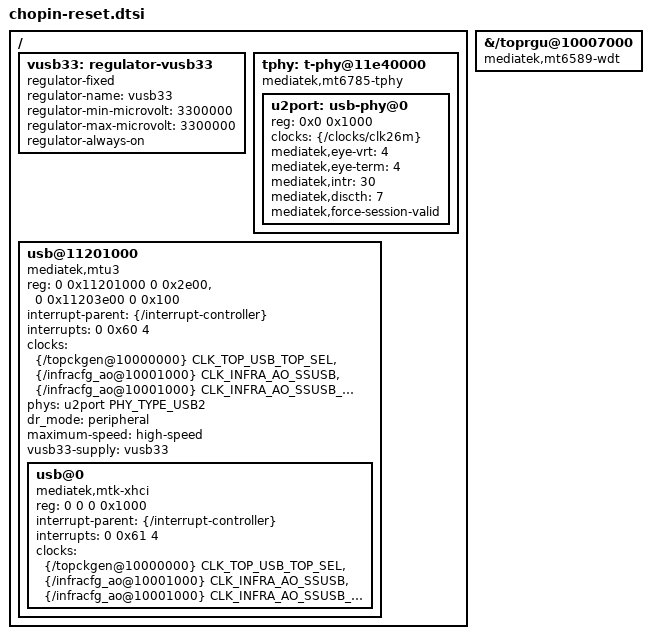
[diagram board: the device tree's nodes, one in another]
// SPDX-License-Identifier: GPL-2.0-only
/*
 * chopin: top reset controller.
 */

&{/toprgu@10007000} {
	compatible = "mediatek,mt6589-wdt", "mediatek,toprgu";
	status = "okay";
};

/ {
	/* mtu3 requires vusb33-supply; LK has already powered it */
	vusb33: regulator-vusb33 {
		compatible = "regulator-fixed";
		regulator-name = "vusb33";
		regulator-min-microvolt = <3300000>;
		regulator-max-microvolt = <3300000>;
		regulator-always-on;
	};

	tphy: t-phy@11e40000 {
		compatible = "mediatek,mt6785-tphy", "mediatek,generic-tphy-v2";
		#address-cells = <1>;
		#size-cells = <1>;
		/*
		 * 4 KiB, not the 0x400 the MT6895 port used: the vendor's
		 * analog rail register (USB30_PHYA_REG1) sits at +0xb04, well
		 * outside a 0x400 window, and the driver has to be able to
		 * reach it.  Everything mainline uses (misc 0x000, freq 0x100,
		 * com 0x300) is unaffected.
		 */
		ranges = <0 0 0x11e40000 0x1000>;
		status = "okay";

		u2port: usb-phy@0 {
			reg = <0x0 0x1000>;
			clocks = <&{/clocks/clk26m}>;
			clock-names = "ref";
			#phy-cells = <1>;

			mediatek,eye-vrt = <4>;
			mediatek,eye-term = <4>;
			mediatek,intr = <30>;
			mediatek,discth = <7>;

			/*
			 * This board does not connect the PHY's VBUS pad to the
			 * Type-C VBUS (the charger IC senses VBUS) and has no
			 * regulator for the PHY's 0.9V analog rail, so the vendor
			 * driver forces the OTG session signals and switches the
			 * rail on.  See the comment in phy-mtk-tphy.c.
			 */
			mediatek,force-session-valid;

			status = "okay";
		};
	};

	usb@11201000 {
		compatible = "mediatek,mtu3";
		reg = <0 0x11201000 0 0x2e00>, <0 0x11203e00 0 0x100>;
		reg-names = "mac", "ippc";
		ranges = <0 0 0 0x11200000 0 0x3f00>;
		#address-cells = <2>;
		#size-cells = <2>;
		interrupt-parent = <&{/interrupt-controller}>;
		interrupts = <0 0x60 4>;
		/*
		 * MediaTek's own mt6893.dtsi (carried in this tree as reference
		 * material) names three clocks here and they map onto our
		 * mainline providers directly:
		 *
		 *   sys_ck  CLK_TOP_USB_TOP_SEL        the top USB mux
		 *   ref_ck  CLK_INFRA_AO_SSUSB         infracfg gate, parent usb_sel
		 *   xhci_ck CLK_INFRA_AO_SSUSB_XHCI    the XHCI block's own gate
		 *
		 * Missing xhci_ck is believed to be why the controller reported a
		 * zero-port root hub: xhci-mtk's port setup only runs when it can
		 * read the IPPC capability, and mtu3's own host setup needs the
		 * block clocked.
		 */
		clocks = <&{/topckgen@10000000} CLK_TOP_USB_TOP_SEL>,
			 <&{/infracfg_ao@10001000} CLK_INFRA_AO_SSUSB>,
			 <&{/infracfg_ao@10001000} CLK_INFRA_AO_SSUSB_XHCI>;
		clock-names = "sys_ck", "ref_ck", "xhci_ck";
		phys = <&u2port PHY_TYPE_USB2>;
		/*
		 * Peripheral (device) mode on purpose: a USB device needs no VBUS
		 * source from us, so it works with nothing but a PC cable, while
		 * host mode would need a 5V OTG regulator that this board tree
		 * does not describe yet (the MT6895 port uses its MT6375 charger
		 * for that).  Device mode is also what gives us a serial console,
		 * which is worth far more right now than a host port.
		 */
		dr_mode = "peripheral";
		maximum-speed = "high-speed";
		vusb33-supply = <&vusb33>;
		status = "okay";

		usb@0 {
			compatible = "mediatek,mtk-xhci";
			reg = <0 0 0 0x1000>;
			reg-names = "mac";
			interrupt-parent = <&{/interrupt-controller}>;
			interrupts = <0 0x61 4>;
			clocks = <&{/topckgen@10000000} CLK_TOP_USB_TOP_SEL>,
				 <&{/infracfg_ao@10001000} CLK_INFRA_AO_SSUSB>,
				 <&{/infracfg_ao@10001000} CLK_INFRA_AO_SSUSB_XHCI>;
			clock-names = "sys_ck", "ref_ck", "xhci_ck";
			status = "okay";
		};
	};

};
/*
 * Dual-role USB.
 *
 * The controller registers a role switch with allow_userspace_control, which is
 * how the port becomes a host: writing "host" to /sys/class/usb_role/<name>/role
 * makes ssusb_set_mode() bring up xhci *and* enable the MT6360's OTG boost through
 * the regulator above.  "device" tears both down again.
 *
 * role-switch-default-mode = "peripheral" is the safety line: the driver reads it
 * (usb_get_role_switch_default_mode()) and starts as a device, so the gadget - and
 * therefore the USB console this port is debugged through - keeps working until
 * someone asks for host.  Without it dr_mode = otg would start as a host and the
 * console would be gone before userspace ever runs.  The initramfs additionally
 * writes "device" to the role switch at startup, and "usbhost <seconds>" opens a
 * timed host window that switches itself back.
 *
 * This override has to sit after the node it patches: dtc resolves &{/path}
 * references while parsing, so placing it earlier fails with "Label or path
 * /usb@11201000 not found".
 */
